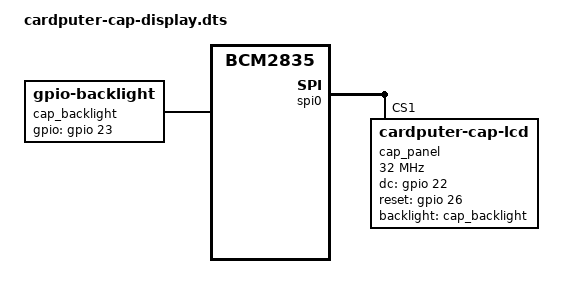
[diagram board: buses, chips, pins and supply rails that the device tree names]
/dts-v1/;
/plugin/;

/*
 * Device Tree Overlay: Secondary SPI CAP Display for M5Stack Cardputer Zero (Rev v5)
 *
 * Exposes an external SPI TFT on the top 14-pin expansion header (EXT 2.54-14P)
 * as a secondary Linux DRM / TinyDRM framebuffer (/dev/fb1 + /dev/fb_cap + /dev/dri/cardputer-zero-cap),
 * WITHOUT interfering with the primary 1.9" ST7789v3 display on SPI0 CE0 (/dev/fb0 / /dev/fb_lcd).
 *
 * Pin mapping (EXT 2.54-14P):
 *   Pin  1 (GPIO26) : LCD RST  (active-high in DT per drm_mipi_dbi.c mipi_dbi_hw_reset())
 *   Pin  3 (GPIO23) : LCD BL   (gpio-backlight, default-on)
 *   Pin  5 (GPIO22) : LCD DC   (Data/Command)
 *   Pin  6 (5V OUT) : LCD VCC  (M5IOE1 ext_5v_out overridden to default-state="on")
 *   Pin  7 (GPIO11) : SPI0_SCLK
 *   Pin  9 (GPIO10) : SPI0_MOSI
 *   Pin 13 (GPIO7)  : SPI0_CE1 (reg = <1>)
 *
 * Compile:
 *   dtc -@ -I dts -O dtb -o cardputer-cap-display.dtbo cardputer-cap-display.dts
 *
 * Firmware file required by panel-mipi-dbi:
 *   /lib/firmware/cardputer-cap-lcd.bin  (generated by gen_panel_fw.py)
 *
 * /boot/firmware/config.txt usage (place AFTER dtoverlay=cardputerzero-v5-overlay):
 *   dtoverlay=cardputer-cap-display
 *   # Optional overrides:
 *   # dtoverlay=cardputer-cap-display,width=320,height=240,speed=32000000
 */

/ {
	compatible = "brcm,bcm2835";

	/* Disable spidev0.1 so panel-mipi-dbi can claim SPI0 CE1 (leave SPI0 CE0 untouched) */
	fragment@0 {
		target = <&spidev1>;
		__overlay__ {
			status = "disabled";
		};
	};

	/* Register secondary MIPI-DBI SPI display on SPI0 CE1 (reg = <1>, GPIO7) */
	fragment@1 {
		target = <&spi0>;
		__overlay__ {
			#address-cells = <1>;
			#size-cells = <0>;
			status = "okay";

			cap_panel: panel@1 {
				compatible = "cardputer-cap-lcd", "panel-mipi-dbi-spi";
				reg = <1>;
				spi-max-frequency = <32000000>;
				dc-gpios = <&gpio 22 0>;
				reset-gpios = <&gpio 26 0>;
				backlight = <&cap_backlight>;
				write-only;
				width-mm = <41>;
				height-mm = <31>;

				cap_timing: panel-timing {
					hactive = <320>;
					vactive = <240>;
					hback-porch = <0>;
					vback-porch = <0>;
					clock-frequency = <0>;
					hfront-porch = <0>;
					hsync-len = <0>;
					vfront-porch = <0>;
					vsync-len = <0>;
				};
			};
		};
	};

	/* GPIO Backlight on Pin 3 (GPIO23) -> /sys/class/backlight/cap-backlight */
	fragment@2 {
		target-path = "/";
		__overlay__ {
			cap_backlight: cap-backlight {
				compatible = "gpio-backlight";
				gpios = <&gpio 23 0>;
				default-on;
			};
		};
	};

	/* Enable Pin 6 (5V OUT) on M5IOE1 at boot so the external screen has power early */
	fragment@3 {
		target-path = "/leds/ext_5v_out";
		__overlay__ {
			default-state = "on";
		};
	};

	/* Optional SPI Mode 3 (CPOL=1, CPHA=1) fragments */
	fragment@4 {
		target = <&cap_panel>;
		__dormant__ {
			spi-cpol;
		};
	};

	fragment@5 {
		target = <&cap_panel>;
		__dormant__ {
			spi-cpha;
		};
	};

	__overrides__ {
		speed     = <&cap_panel>, "spi-max-frequency:0";
		width     = <&cap_timing>, "hactive:0";
		height    = <&cap_timing>, "vactive:0";
		x-offset  = <&cap_timing>, "hback-porch:0";
		y-offset  = <&cap_timing>, "vback-porch:0";
		width-mm  = <&cap_panel>, "width-mm:0";
		height-mm = <&cap_panel>, "height-mm:0";
		dc-pin    = <&cap_panel>, "dc-gpios:4";
		reset-pin = <&cap_panel>, "reset-gpios:4";
		bl-pin    = <&cap_backlight>, "gpios:4";
		cpol      = <0>, "+4";
		cpha      = <0>, "+5";
	};
};
